AUTOSAR XML (schema 4-2-2)
package /Components
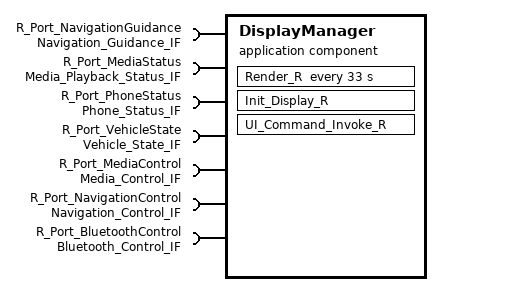
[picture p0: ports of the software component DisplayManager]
  application sw component type DisplayManager
    7 x require port:
      R_Port_NavigationGuidance: required-interface=Navigation_Guidance_IF
      R_Port_MediaStatus: required-interface=Media_Playback_Status_IF
      R_Port_PhoneStatus: required-interface=Phone_Status_IF
      R_Port_VehicleState: required-interface=Vehicle_State_IF
      R_Port_MediaControl: required-interface=Media_Control_IF
      R_Port_NavigationControl: required-interface=Navigation_Control_IF
      R_Port_BluetoothControl: required-interface=Bluetooth_Control_IF
    behavior DisplayManager_Internal
      init event Display_Init: start-on-event=Init_Display_R
      timing event Display_Render: start-on-event=Render_R, period=33
      runnable Init_Display_R
        parameter access ParamAccess_DisplayTheme: accessed-parameter=R_Port_MediaStatus.play_state
        parameter access ParamAccess_LayoutMode: accessed-parameter=R_Port_NavigationGuidance.turn_type
      runnable Render_R: minimum-start-interval=33
        data-receive-point-by-arguments:
          10 x access:
            Read_Nav_TurnType: accessed-variable=R_Port_NavigationGuidance.turn_type
            Read_Nav_DistanceToTurn: accessed-variable=R_Port_NavigationGuidance.distance_to_turn_m
            Read_Nav_LaneRecommendation: accessed-variable=R_Port_NavigationGuidance.lane_recommendation
            Read_Media_PlayState: accessed-variable=R_Port_MediaStatus.play_state
            Read_Media_TrackTitle: accessed-variable=R_Port_MediaStatus.track_title
            Read_Media_ElapsedMs: accessed-variable=R_Port_MediaStatus.elapsed_ms
            Read_Phone_CallState: accessed-variable=R_Port_PhoneStatus.call_state
            Read_Phone_CallerId: accessed-variable=R_Port_PhoneStatus.caller_id
            Read_Vehicle_SpeedKph: accessed-variable=R_Port_VehicleState.vehicle_speed_kph
            Read_Vehicle_Gear: accessed-variable=R_Port_VehicleState.vehicle_gear
        parameter access ParamAccess_Render_UpdateRate: accessed-parameter=R_Port_VehicleState.vehicle_speed_kph
        parameter access ParamAccess_Render_GearScale: accessed-parameter=R_Port_VehicleState.vehicle_gear
      runnable UI_Command_Invoke_R: minimum-start-interval=10, can-be-invoked-concurrently=true
        15 x sync call:
          SC_Media_Play: operation=R_Port_MediaControl.Play, timeout=50
          SC_Media_Pause: operation=R_Port_MediaControl.Pause, timeout=50
          SC_Media_Stop: operation=R_Port_MediaControl.Stop, timeout=50
          SC_Media_NextTrack: operation=R_Port_MediaControl.NextTrack, timeout=50
          SC_Media_PreviousTrack: operation=R_Port_MediaControl.PreviousTrack, timeout=50
          SC_Media_SetSource: operation=R_Port_MediaControl.SetSource, timeout=50
          SC_Nav_StartRoute: operation=R_Port_NavigationControl.StartRoute, timeout=200
          SC_Nav_CancelRoute: operation=R_Port_NavigationControl.CancelRoute, timeout=200
          SC_Nav_SetDestination: operation=R_Port_NavigationControl.SetDestination, timeout=200
          SC_BT_Pair: operation=R_Port_BluetoothControl.Pair, timeout=200
          SC_BT_ConnectAudio: operation=R_Port_BluetoothControl.ConnectAudio, timeout=200
          SC_BT_ConnectPhone: operation=R_Port_BluetoothControl.ConnectPhone, timeout=200
          SC_BT_DialNumber: operation=R_Port_BluetoothControl.DialNumber, timeout=200
          SC_BT_AnswerCall: operation=R_Port_BluetoothControl.AnswerCall, timeout=200
          SC_BT_Hangup: operation=R_Port_BluetoothControl.Hangup, timeout=200
